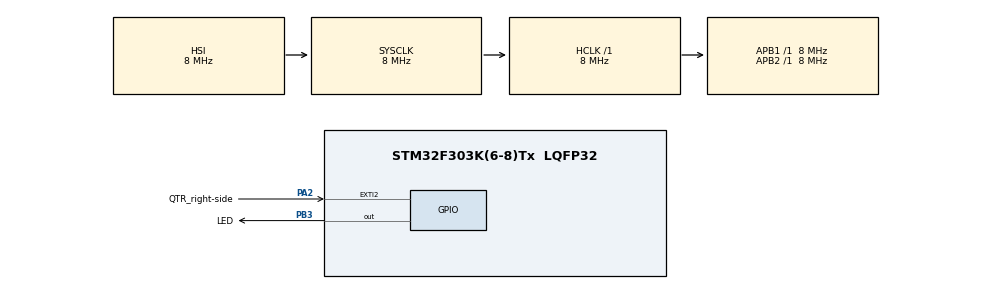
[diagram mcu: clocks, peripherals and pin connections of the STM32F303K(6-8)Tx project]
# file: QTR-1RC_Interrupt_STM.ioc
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Mcu.Family=STM32F3
Mcu.Name=STM32F303K(6-8)Tx
Mcu.Package=LQFP32
NVIC.EXTI2_TSC_IRQn=true\:0\:0\:false\:false\:true\:true\:true
NVIC.PriorityGroup=NVIC_PRIORITYGROUP_4
PA2.GPIO_Label=QTR_right-side
PA2.GPIO_ModeDefaultEXTI=GPIO_MODE_IT_RISING_FALLING
PA2.Signal=GPXTI2
PB3.GPIO_Label=LED
PB3.Signal=GPIO_Output
ProjectManager.HeapSize=0x200
ProjectManager.StackSize=0x400
ProjectManager.TargetToolchain=TrueSTUDIO
RCC.AHBFreq_Value=8000000
RCC.APB1Freq_Value=8000000
RCC.APB2Freq_Value=8000000
RCC.CortexFreq_Value=8000000
RCC.HSE_VALUE=8000000
RCC.HSI_VALUE=8000000
RCC.SYSCLKFreq_VALUE=8000000
board=custom

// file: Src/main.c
/* USER CODE BEGIN Header */
/**
  ******************************************************************************
  * @file           : main.c
  * @brief          : Main program body
  ******************************************************************************
  * @attention
  *
  * <h2><center>&copy; Copyright (c) 2019 STMicroelectronics.
  * All rights reserved.</center></h2>
  *
  * This software component is licensed by ST under BSD 3-Clause license,
  * the "License"; You may not use this file except in compliance with the
  * License. You may obtain a copy of the License at:
  *                        opensource.org/licenses/BSD-3-Clause
  *
  ******************************************************************************
  */
/* USER CODE END Header */

#include "main.h"

void SystemClock_Config(void);
static void MX_GPIO_Init(void);

/* USER CODE BEGIN 0 */
uint8_t Rside_state=0;
/* USER CODE END 0 */

int main(void)
{

  /* MCU Configuration--------------------------------------------------------*/

  /* Reset of all peripherals, Initializes the Flash interface and the Systick. */
  HAL_Init();

  /* Configure the system clock */
  SystemClock_Config();

  /* Initialize all configured peripherals */
  MX_GPIO_Init();

  /* Infinite loop */
  while (1)
  {

    /* USER CODE BEGIN 3 */
	  HAL_GPIO_WritePin(GPIOB, LED_Pin, (GPIO_PinState)Rside_state);
  }
  /* USER CODE END 3 */
}

void SystemClock_Config(void)
{
  RCC_OscInitTypeDef RCC_OscInitStruct = {0};
  RCC_ClkInitTypeDef RCC_ClkInitStruct = {0};

  /** Initializes the CPU, AHB and APB busses clocks
  */
  RCC_OscInitStruct.OscillatorType = RCC_OSCILLATORTYPE_HSI;
  RCC_OscInitStruct.HSIState = RCC_HSI_ON;
  RCC_OscInitStruct.HSICalibrationValue = RCC_HSICALIBRATION_DEFAULT;
  RCC_OscInitStruct.PLL.PLLState = RCC_PLL_NONE;
  if (HAL_RCC_OscConfig(&RCC_OscInitStruct) != HAL_OK)
  {
    Error_Handler();
  }
  /** Initializes the CPU, AHB and APB busses clocks
  */
  RCC_ClkInitStruct.ClockType = RCC_CLOCKTYPE_HCLK|RCC_CLOCKTYPE_SYSCLK
                              |RCC_CLOCKTYPE_PCLK1|RCC_CLOCKTYPE_PCLK2;
  RCC_ClkInitStruct.SYSCLKSource = RCC_SYSCLKSOURCE_HSI;
  RCC_ClkInitStruct.AHBCLKDivider = RCC_SYSCLK_DIV1;
  RCC_ClkInitStruct.APB1CLKDivider = RCC_HCLK_DIV1;
  RCC_ClkInitStruct.APB2CLKDivider = RCC_HCLK_DIV1;

  if (HAL_RCC_ClockConfig(&RCC_ClkInitStruct, FLASH_LATENCY_0) != HAL_OK)
  {
    Error_Handler();
  }
}

static void MX_GPIO_Init(void)
{
  GPIO_InitTypeDef GPIO_InitStruct = {0};

  /* GPIO Ports Clock Enable */
  __HAL_RCC_GPIOA_CLK_ENABLE();
  __HAL_RCC_GPIOB_CLK_ENABLE();

  /*Configure GPIO pin Output Level */
  HAL_GPIO_WritePin(LED_GPIO_Port, LED_Pin, GPIO_PIN_RESET);

  /*Configure GPIO pin : QTR_right_side_Pin */
  GPIO_InitStruct.Pin = QTR_right_side_Pin;
  GPIO_InitStruct.Mode = GPIO_MODE_IT_RISING_FALLING;
  GPIO_InitStruct.Pull = GPIO_NOPULL;
  HAL_GPIO_Init(QTR_right_side_GPIO_Port, &GPIO_InitStruct);

  /*Configure GPIO pin : LED_Pin */
  GPIO_InitStruct.Pin = LED_Pin;
  GPIO_InitStruct.Mode = GPIO_MODE_OUTPUT_PP;
  GPIO_InitStruct.Pull = GPIO_NOPULL;
  GPIO_InitStruct.Speed = GPIO_SPEED_FREQ_LOW;
  HAL_GPIO_Init(LED_GPIO_Port, &GPIO_InitStruct);

  /* EXTI interrupt init*/
  HAL_NVIC_SetPriority(EXTI2_TSC_IRQn, 0, 0);
  HAL_NVIC_EnableIRQ(EXTI2_TSC_IRQn);

}

/* USER CODE BEGIN 4 */
void HAL_GPIO_EXTI_Callback(uint16_t GPIO_Pin)
{
	if(GPIO_Pin==QTR_right_side_Pin)
	{
		if(Rside_state==0)
			Rside_state=1;
		else
			Rside_state=0;
	}
}
/* USER CODE END 4 */

void Error_Handler(void)
{
}

/************************ (C) COPYRIGHT STMicroelectronics *****END OF FILE****/
